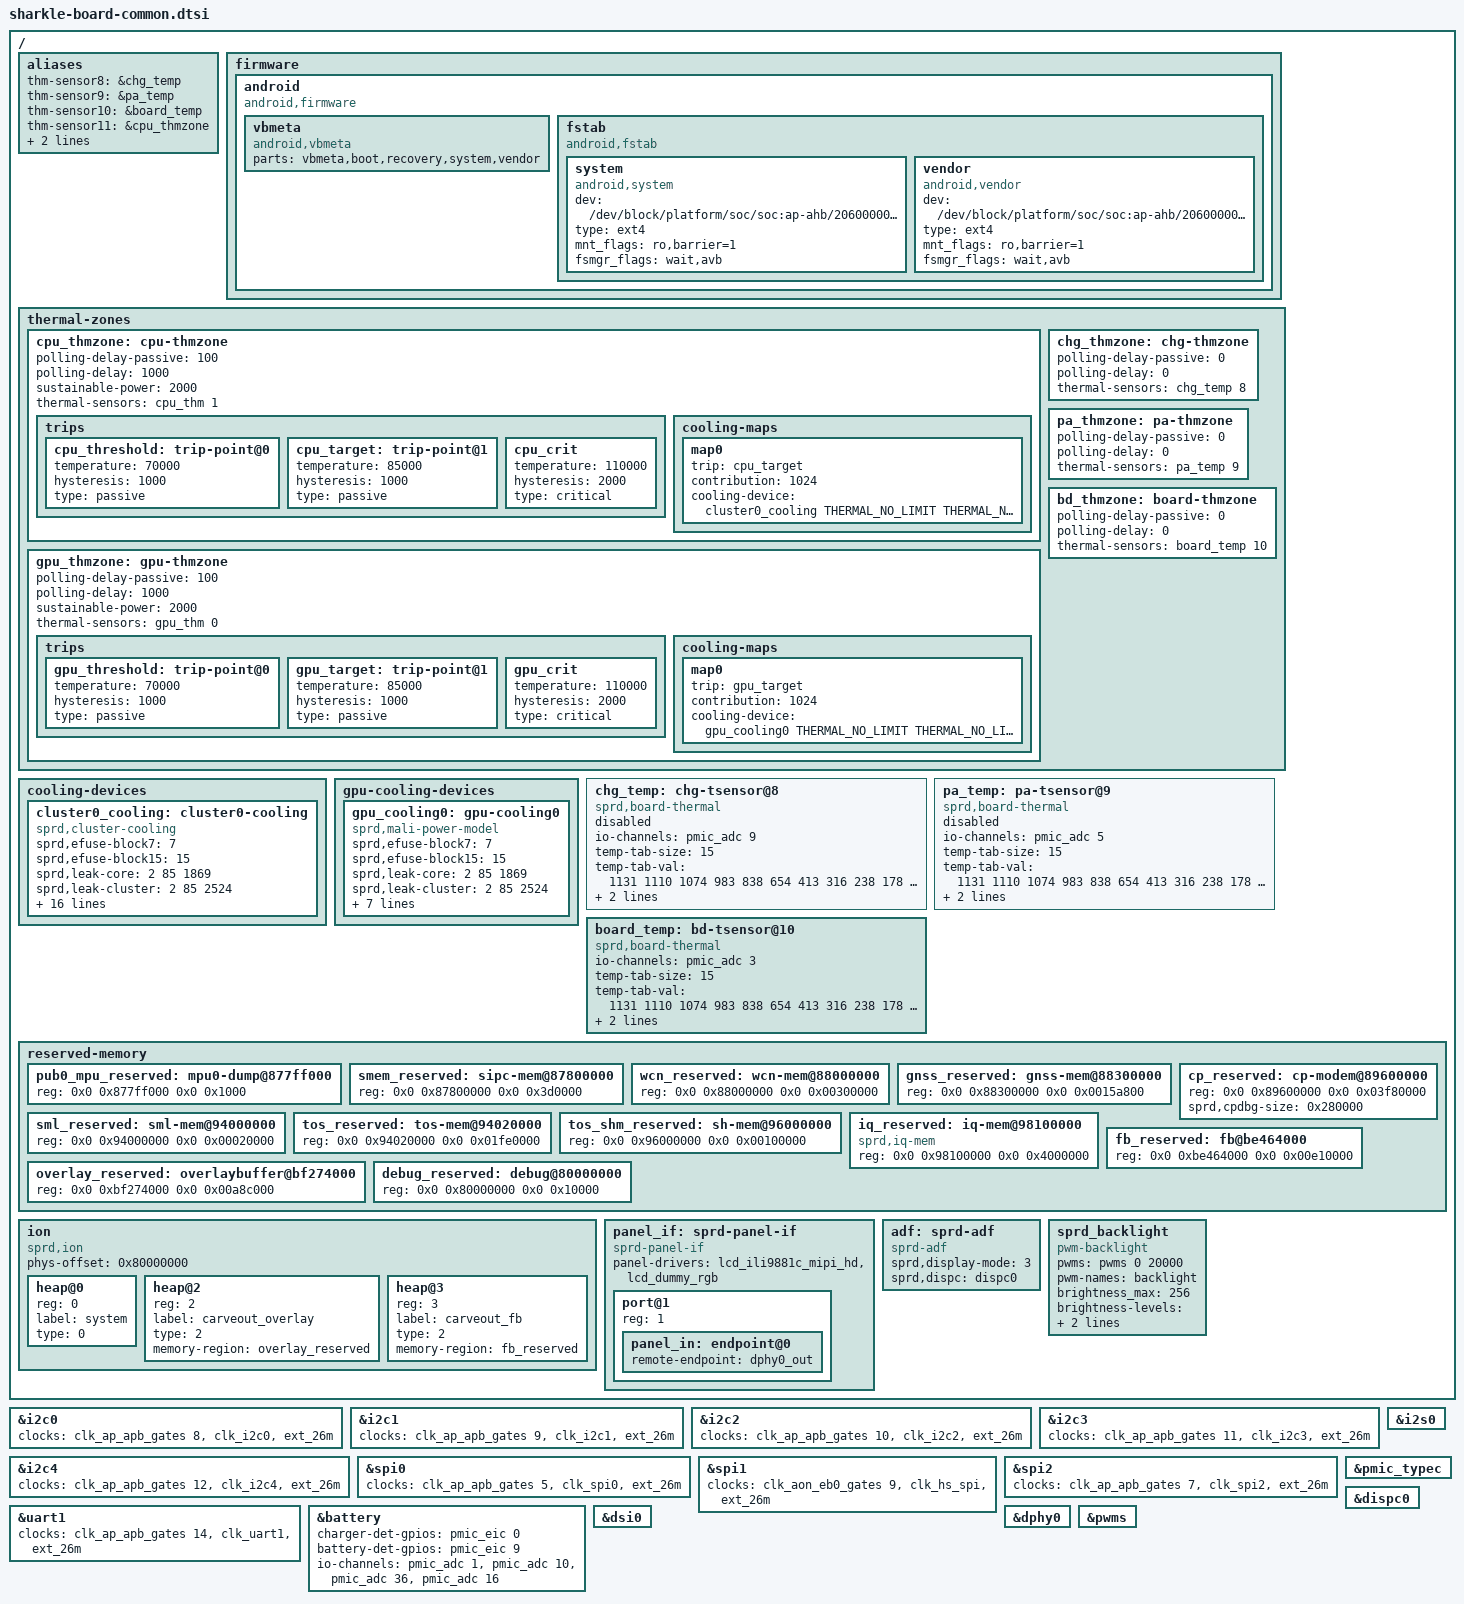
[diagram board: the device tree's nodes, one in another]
/*
 * Spreadtrum SP98x0 board common DTS file
 *
 * Copyright (C) 2017, Spreadtrum Communications Inc.
 *
 * This file is licensed under a dual GPLv2 or X11 license.
 */

#include "sc2721.dtsi"
#include "sc9832e-modem.dtsi"
#include "sc9832e-wcn.dtsi"
#include "sprd-battery.dtsi"
#include "sprd-sound-sharkl.dtsi"
#include "lcd/lcd_ili9881c_mipi_hd.dtsi"
#include "lcd/lcd_dummy_rgb.dtsi"
#include <dt-bindings/thermal/thermal.h>

/ {
	aliases {
		thm-sensor8 = &chg_temp;
		thm-sensor9 = &pa_temp;
		thm-sensor10 = &board_temp;
		thm-sensor11 = &cpu_thmzone;
		cooling-device0 = &cluster0_cooling;
		gpu-cooling0 = &gpu_cooling0;
	};

	firmware {
		android {
			compatible = "android,firmware";

			vbmeta {
				compatible = "android,vbmeta";
				parts = "vbmeta,boot,recovery,system,vendor";
			};
			fstab {
				compatible = "android,fstab";
				system {
					compatible = "android,system";
					dev = "/dev/block/platform/soc/soc:ap-ahb/20600000.sdio/by-name/system";
					type = "ext4";
					mnt_flags = "ro,barrier=1";
					fsmgr_flags = "wait,avb";
				};
				vendor {
					compatible = "android,vendor";
					dev = "/dev/block/platform/soc/soc:ap-ahb/20600000.sdio/by-name/vendor";
					type = "ext4";
					mnt_flags = "ro,barrier=1";
					fsmgr_flags = "wait,avb";
				};
			};
		};
	};

	thermal-zones {

		cpu_thmzone: cpu-thmzone {
			polling-delay-passive = <100>;
			polling-delay = <1000>;
			sustainable-power = <2000>;
			thermal-sensors = <&cpu_thm  1>;
			trips {
				cpu_threshold: trip-point@0 {
					temperature = <70000>;
					hysteresis = <1000>;
					type = "passive";
				};
				cpu_target: trip-point@1 {
					temperature = <85000>;
					hysteresis = <1000>;
					type = "passive";
				};
				cpu_crit: cpu_crit {
					temperature = <110000>;
					hysteresis = <2000>;
					type = "critical";
				};
			};

			cooling-maps {
				map0 {
					trip = <&cpu_target>;
					contribution = <1024>;
					cooling-device =
					<&cluster0_cooling
						THERMAL_NO_LIMIT
						THERMAL_NO_LIMIT>;
				};
			};
		};

		gpu_thmzone: gpu-thmzone {
			polling-delay-passive = <100>;
			polling-delay = <1000>;
			sustainable-power = <2000>;
			thermal-sensors = <&gpu_thm  0>;
			trips {
				gpu_threshold: trip-point@0 {
					temperature = <70000>;
					hysteresis = <1000>;
					type = "passive";
				};
				gpu_target: trip-point@1 {
					temperature = <85000>;
					hysteresis = <1000>;
					type = "passive";
				};
				gpu_crit: gpu_crit {
					temperature = <110000>;
					hysteresis = <2000>;
					type = "critical";
				};
			};

			cooling-maps {
				map0 {
					trip = <&gpu_target>;
					contribution = <1024>;
					cooling-device =
					<&gpu_cooling0
						THERMAL_NO_LIMIT
						THERMAL_NO_LIMIT>;
				};
			};
		};

		chg_thmzone: chg-thmzone {
			polling-delay-passive = <0>;
			polling-delay = <0>;
			thermal-sensors = <&chg_temp  8>;
		};

		pa_thmzone: pa-thmzone {
			polling-delay-passive = <0>;
			polling-delay = <0>;
			thermal-sensors = <&pa_temp  9>;
		};

		bd_thmzone: board-thmzone {
			polling-delay-passive = <0>;
			polling-delay = <0>;
			thermal-sensors = <&board_temp  10>;
		};
	};

	cooling-devices {
		cluster0_cooling: cluster0-cooling {
			compatible = "sprd,cluster-cooling";
			#cooling-cells = <2>; /* min followed by max */
			sprd,efuse-block7 = <7>;
			sprd,efuse-block15 = <15>;
			/* core_leak =                             */
			/*(LIT_LEAK[4:0]+1) x 2mA x 0.85V x 18.69% */
			sprd,leak-core = <2 85 1869>;
			/* cluster_leak =                           */
			/* (LIT_LEAK[4:0]+1) x 2mA x 0.85V x 25.24% */
			sprd,leak-cluster = <2 85 2524>;
			/*core Tscale = aT^3 + bT^2 + cT +di   */
			sprd,core-temp-scale =
			/* a*10^7   b*10^7      c*10^7     d*10^7 */
			<  34       (-3000)     147000     (-1367000)>;
			/*core Vscale = eV^3 + fV^2 + gV + h */
			sprd,core-voltage-scale =
			/* e*10^2   f*10^2     g*10^2  h*10^2*/
			<  2863     (-7860)    7541    (-2408)>;
			/*cluster Tscale = aT^3 + bT^2 + cT +di   */
			sprd,cluster-temp-scale =
			/* a*10^7   b*10^7      c*10^7     d*10^7 */
			<  26       (-2000)     115000     (-1000000)>;
			/*cluster Vscale = eV^3 + fV^2 + gV + h */
			sprd,cluster-voltage-scale =
			/* e*10^2   f*10^2     g*10^2  h*10^2*/
			<  1582     (-4201)    4063    (-1307)>;
			sprd,efuse-switch = <0>;
			sprd,hotplug-period = <0>;
			sprd,min-cpufreq = <768000>;
			sprd,min-cpunum = <4>;
			sprd,core-base = <267>;
			sprd,cluster-base = <294>;
			sprd,dynamic-core =
			/*Pdynperghz    Freq     Vbase  */
			< 850          768       900>;
			sprd,dynamic-cluster =
			/*Pdynperghz    Freq     Vbase  */
			< 980           768      900>;
		};
	};

	gpu-cooling-devices {
		gpu_cooling0: gpu-cooling0 {
			compatible = "sprd,mali-power-model";
			#cooling-cells = <2>;
			sprd,efuse-block7 = <7>;
			sprd,efuse-block15 = <15>;
			/* core_leak =                             */
			/*(LIT_LEAK[4:0]+1) x 2mA x 0.85V x 18.69% */
			sprd,leak-core = <2 85 1869>;
			/* cluster_leak =                           */
			/* (LIT_LEAK[4:0]+1) x 2mA x 0.85V x 25.24% */
			sprd,leak-cluster = <2 85 2524>;
			/*Tscale = aT^3 + bT^2 + cT +di   */
			sprd,temp-scale =
			/* a*10^7   b*10^7      c*10^7     d*10^7 */
			<  400      100        100000    6940000>;
			/*Vscale = eV^3 + fV^2 + gV + h */
			sprd,voltage-scale =
			/* e*10^2   f*10^2     g*10^2  h*10^2*/
			<  195      (-358)     343     91>;
			sprd,hotplug-period = <0>;
			sprd,core-base = <716>;
			sprd,cluster-base = <0>;
			sprd,dynamic-core =
			/*Pdynperghz    Freq     Vbase  */
			< 9230           768     1050>;
			sprd,dynamic-cluster =
			/*Pdynperghz    Freq     Vbase  */
			< 0              0       0>;
		};
	};

	chg_temp:chg-tsensor@8 {
		compatible = "sprd,board-thermal";
		#thermal-sensor-cells = <1>;
		io-channels = <&pmic_adc 9>;
		io-channel-names = "adc_temp";
		temp-tab-size = <15>;
		temp-tab-val = <1131 1110 1074 983 838 654 413
				316 238 178 133 100 75 57 43>;
		temp-tab-temp = <603 702 805 952 1101 1248 1449
				1549 1649 1749 1849 1949 2049 2149 2249>;
	};

	pa_temp:pa-tsensor@9 {
		compatible = "sprd,board-thermal";
		#thermal-sensor-cells = <1>;
		io-channels = <&pmic_adc 5>;
		io-channel-names = "adc_temp";
		temp-tab-size = <15>;
		temp-tab-val = <1131 1110 1074 983 838 654 413
				316 238 178 133 100 75 57 43>;
		temp-tab-temp = <603 702 805 952 1101 1248 1449
				1549 1649 1749 1849 1949 2049 2149 2249>;
	};

	board_temp:bd-tsensor@10 {
		compatible = "sprd,board-thermal";
		#thermal-sensor-cells = <1>;
		io-channels = <&pmic_adc 3>;
		io-channel-names = "adc_temp";
		temp-tab-size = <15>;
		temp-tab-val = <1131 1110 1074 983 838 654 413
				316 238 178 133 100 75 57 43>;
		temp-tab-temp = <603 702 805 952 1101 1248 1449
				1549 1649 1749 1849 1949 2049 2149 2249>;
	};

	/* smartphone board only */
	reserved-memory {
		#address-cells = <2>;
		#size-cells = <2>;
		ranges;

		pub0_mpu_reserved: mpu0-dump@877ff000 {
			reg = <0x0 0x877ff000 0x0 0x1000>;
		};

		smem_reserved: sipc-mem@87800000 {
			reg = <0x0 0x87800000 0x0 0x3d0000>;
		};

		/* must be 32M aligned */
		wcn_reserved: wcn-mem@88000000{
			reg = <0x0 0x88000000 0x0 0x00300000>;
		};

		gnss_reserved: gnss-mem@88300000{
			reg = <0x0 0x88300000 0x0 0x0015a800>;
		};

		/* cp_reserved = cp region + debug region */
		/* debug region: not reserved in normal mode, it */
		/* will be proccessed in u-boot */
		cp_reserved: cp-modem@89600000 {
			reg = <0x0 0x89600000 0x0 0x03f80000>;
			/* This prop specifies the size of debug region */
			/* in the cp tail */
			sprd,cpdbg-size = <0x280000>;
		};

		/* must be 64M aligned */
		sml_reserved: sml-mem@94000000{
			reg = <0x0 0x94000000 0x0 0x00020000>;
		};

		tos_reserved: tos-mem@94020000{
			reg = <0x0 0x94020000 0x0 0x01fe0000>;
		};

		tos_shm_reserved: sh-mem@96000000{
			reg = <0x0 0x96000000 0x0 0x00100000>;
		};

		/* Only used for iq, will be removed in normal mode by uboot */
		iq_reserved: iq-mem@98100000{
			compatible = "sprd,iq-mem";
			reg = <0x0 0x98100000 0x0 0x4000000>;
		};

		/* if changed ,uboot dts also need change */
		fb_reserved: fb@be464000{
			reg = <0x0 0xbe464000 0x0 0x00e10000>;
		};

		overlay_reserved: overlaybuffer@bf274000{
			reg = <0x0 0xbf274000 0x0 0x00a8c000>;
		};

		debug_reserved: debug@80000000{
		reg = <0x0 0x80000000 0x0 0x10000>;
		};
	};

	ion {
		compatible = "sprd,ion";
		#address-cells = <1>;
		#size-cells = <0>;
		phys-offset = <0x80000000>;

		heap@0 {
			reg = <0>;
			label = "system";
			type = <0>;
		};

		heap@2 {
			reg = <2>;
			label = "carveout_overlay";
			type = <2>;
			memory-region = <&overlay_reserved>;
		};

		heap@3 {
			reg = <3>;
			label = "carveout_fb";
			type = <2>;
			memory-region = <&fb_reserved>;
		};
	};

	panel_if: sprd-panel-if {
		compatible = "sprd-panel-if";
		#address-cells = <1>;
		#size-cells = <0>;
		panel-drivers = <
			&lcd_ili9881c_mipi_hd
			&lcd_dummy_rgb
		>;

		/* input port */
		port@1 {
		/* WARNING: the reg property must be 1 ! */
			reg = <1>;
			panel_in: endpoint@0 {
				remote-endpoint = <&dphy0_out>;
			};
		};
	};

	adf: sprd-adf {
		compatible = "sprd-adf";
		status = "okay";
		sprd,display-mode = <3>;
		sprd,dispc = <&dispc0>;
	};

	sprd_backlight {
		compatible = "pwm-backlight";
		pwms = <&pwms 0 20000>;
		pwm-names = "backlight";
		brightness_max = <256>;
		brightness-levels = <
						3   3   3   3
			3   3   3   3   4   5   6   7   8   9
			10  11  12  13  14  15  16  17  18  19
			20  21  22  23  24  25  26  27  28  29
			30  31  32  33  34  35  36  37  38  39
			40  41  42  43  44  45  46  47  48  49
			50  51  52  53  54  55  56  57  58  59
			60  61  62  63  64  65  66  67  68  69
			70  71  72  73  74  75  76  77  78  79
			80  81  82  83  84  85  86  87  88  89
			90  91  92  93  94  95  96  97  98  99
			100 101 102 103 104 105 106 107 108 109
			110 111 112 113 114 115 116 117 118 119
			120 121 122 123 124 125 126 127 128 129
			130 131 132 133 134 135 136 137 138 139
			140 141 142 143 144 145 146 147 148 149
			150 151 152 153 154 155 156 157 158 159
			160 161 162 163 164 165 166 167 168 169
			170 171 172 173 174 175 176 177 178 179
			180 181 182 183 184 185 186 187 188 189
			190 191 192 193 194 195 196 197 198 199
			200 201 202 203 204 205 206 207 208 209
			210 211 212 213 214 215 216 217 218 219
			220 221 222 223 224 225 226 227 228 229
			230 231 232 233 234 235 236 237 238 239
			240 241 242 243 244 245 246 247 248 249
			250 251
			>;
		default-brightness-level = <25>;
	};

};

&i2c0 {
	clocks = <&clk_ap_apb_gates 8>, <&clk_i2c0>, <&ext_26m>;
};

&i2c1 {
	clocks = <&clk_ap_apb_gates 9>, <&clk_i2c1>, <&ext_26m>;
};

&i2c2 {
	clocks = <&clk_ap_apb_gates 10>, <&clk_i2c2>, <&ext_26m>;
};

&i2c3 {
	clocks = <&clk_ap_apb_gates 11>, <&clk_i2c3>, <&ext_26m>;
};

&i2c4 {
	clocks = <&clk_ap_apb_gates 12>, <&clk_i2c4>, <&ext_26m>;
};

&spi0 {
	clocks = <&clk_ap_apb_gates 5>, <&clk_spi0>, <&ext_26m>;
};

&spi1 {
	clocks = <&clk_aon_eb0_gates 9>, <&clk_hs_spi>, <&ext_26m>;
};

&spi2 {
	clocks = <&clk_ap_apb_gates 7>, <&clk_spi2>, <&ext_26m>;
};

&uart1 {
	clocks = <&clk_ap_apb_gates 14>, <&clk_uart1>, <&ext_26m>;
	status = "okay";
};

&i2s0 {
	status = "okay";
};

&battery {
	charger-det-gpios = <&pmic_eic 0 0>;
	battery-det-gpios = <&pmic_eic 9 0>;
	io-channels = <&pmic_adc 1>,<&pmic_adc 10>,
		<&pmic_adc 36>,<&pmic_adc 16>;
	io-channel-names = "adc_temp","adc_vbat",
		"adc_vchg","adc_isense";
	status = "okay";
};

&pmic_typec {
	status = "okay";
};

&dispc0 {
	status = "okay";
};

&dsi0 {
	status = "okay";
};

&dphy0 {
	status = "okay";
};

&pwms {
	status = "okay";
};

&chg_temp {
	status = "disabled";
};

&pa_temp {
	status = "disabled";
};
